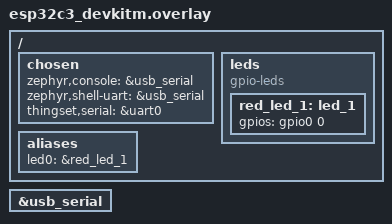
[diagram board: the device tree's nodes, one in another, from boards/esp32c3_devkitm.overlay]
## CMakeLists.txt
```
# Copyright (c) The ThingSet Project Contributors
# SPDX-License-Identifier: Apache-2.0

cmake_minimum_required(VERSION 3.13.1)
find_package(Zephyr REQUIRED HINTS $ENV{ZEPHYR_BASE})

project(thingset_sample_counter)

target_include_directories(app PRIVATE src)

# hack required for ESP32-C3 to keep USB serial enabled when BLE or WiFi is used
zephyr_compile_definitions(CONFIG_ESP_PHY_ENABLE_USB)

target_sources(app PRIVATE src/main.c)
zephyr_sources_ifdef(CONFIG_THINGSET_CAN src/can.c)
```

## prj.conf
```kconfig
# Copyright (c) The ThingSet Project Contributors
# SPDX-License-Identifier: Apache-2.0

CONFIG_SERIAL=y
CONFIG_UART_INTERRUPT_DRIVEN=y

CONFIG_STDOUT_CONSOLE=y
CONFIG_CBPRINTF_FP_SUPPORT=y

CONFIG_LOG=y

# ThingSet library
CONFIG_THINGSET=y

# ThingSet SDK
CONFIG_THINGSET_SDK=y
CONFIG_THINGSET_REPORTING_LIVE_ENABLE_PRESET=n
CONFIG_THINGSET_SERIAL=y
CONFIG_THINGSET_SERIAL_RX_BUF_SIZE=2048

CONFIG_BT=y
CONFIG_BT_PERIPHERAL=y
CONFIG_BT_DEVICE_NAME="ThingSet Gateway"
CONFIG_BT_DEVICE_NAME_DYNAMIC=y
CONFIG_BT_GATT_CLIENT=y

# Increase buffer sizes to allow long ATT values
CONFIG_BT_BUF_ACL_RX_SIZE=251
CONFIG_BT_BUF_ACL_TX_SIZE=251
CONFIG_BT_L2CAP_TX_MTU=251

CONFIG_THINGSET_BLE=y
CONFIG_THINGSET_BLE_RX_BUF_SIZE=2048
```

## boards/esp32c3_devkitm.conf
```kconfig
# Disable logging as it may confuse the ThingSet serial
CONFIG_LOG=n
```

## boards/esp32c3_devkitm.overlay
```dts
/*
 * Copyright (c) The ThingSet Project Contributors
 *
 * SPDX-License-Identifier: Apache-2.0
 */

/ {
	chosen {
		zephyr,console = &usb_serial;
		zephyr,shell-uart = &usb_serial;
		thingset,serial = &uart0;
	};

	leds {
		compatible = "gpio-leds";
		red_led_1: led_1 {
			gpios = <&gpio0 0 GPIO_ACTIVE_HIGH>;
		};
	};

	aliases {
		led0 = &red_led_1;
	};
};

&usb_serial {
	status = "okay";
};
```

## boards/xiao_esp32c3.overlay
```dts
/*
 * Copyright (c) The ThingSet Project Contributors
 *
 * SPDX-License-Identifier: Apache-2.0
 */

/ {
	chosen {
		thingset,serial = &uart0;
	};

	leds {
		compatible = "gpio-leds";
		red_led_1: led_1 {
			gpios = <&gpio0 0 GPIO_ACTIVE_HIGH>;
		};
	};

	aliases {
		led0 = &red_led_1;
	};
};
```

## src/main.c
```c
/*
 * Copyright (c) The ThingSet Project Contributors
 *
 * SPDX-License-Identifier: Apache-2.0
 */

#include <zephyr/drivers/gpio.h>
#include <zephyr/kernel.h>

#include "thingset/ble.h"
#include "thingset/sdk.h"
#include "thingset/serial.h"

#define LED0_NODE DT_ALIAS(led0)

static const struct gpio_dt_spec led = GPIO_DT_SPEC_GET(LED0_NODE, gpios);

void switch_led_off(struct k_timer *timer)
{
    if (device_is_ready(led.port)) {
        gpio_pin_set_dt(&led, 0);
    }
}

K_TIMER_DEFINE(led_off_timer, switch_led_off, NULL);

void flash_led()
{
    if (device_is_ready(led.port)) {
        gpio_pin_set_dt(&led, 1);
        k_timer_start(&led_off_timer, K_MSEC(100), K_NO_WAIT);
    }
}

void serial_rx_callback(const uint8_t *buf, size_t len)
{
    thingset_ble_send(buf, len);
    flash_led();
}

void ble_rx_callback(const uint8_t *buf, size_t len)
{
    thingset_serial_send(buf, len);
    flash_led();
}

int main(void)
{
    thingset_serial_set_rx_callback(serial_rx_callback);
    thingset_ble_set_rx_callback(ble_rx_callback);

    if (!device_is_ready(led.port)) {
        /* ignore LED if not available */
        return 0;
    }

    /* blink LED once to indicate start-up of the board */
    gpio_pin_configure_dt(&led, GPIO_OUTPUT_ACTIVE);
    k_sleep(K_SECONDS(1));
    gpio_pin_set_dt(&led, 0);

    return 0;
}
```
